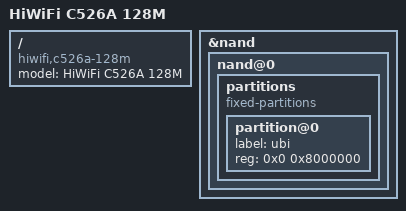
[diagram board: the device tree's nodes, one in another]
// SPDX-License-Identifier: GPL-2.0-or-later OR MIT

#include "qcom-ipq4019-c526a.dtsi"

/ {
	model = "HiWiFi C526A 128M";
	compatible = "hiwifi,c526a-128m";
};

&nand {
	status = "okay";

	nand@0 {
		partitions {
			compatible = "fixed-partitions";
			#address-cells = <1>;
			#size-cells = <1>;

			partition@0 {
				label = "ubi";
				reg = <0x0 0x8000000>;
			};
		};
	};
};
